AUTOSAR XML (schema 4-2-1)
standard types defined: boolean, uint16, uint32, uint8
package /VehicleProject
  system System
package /NM
  nm config NmConfig: can-nm-cluster-coupling=coupled-cluster=NIO_ES6_RF_CAN_SR_V3_0_CAN
    can nm cluster NIO_ES6_RF_CAN_SR_V3_0_CAN: communication-cluster=NIO_ES6_RF_CAN_SR_V3_0, nm-channel-id=0, nm-msg-cycle-time=0.64, nm-network-timeout=2, nm-repeat-message-time=3.2, nm-user-data-length=6, nm-wait-bus-sleep-time=2
      can nm node CGW: nm-if-ecu=CGW_CAN, nm-node-id=5, rx-nm-pdu=NM_WLC_oNIO_ES6_RF_CAN_SR_V3_0, tx-nm-pdu=NM_CGW_oNIO_ES6_RF_CAN_SR_V3_0, nm-msg-cycle-offset=0, nm-msg-reduced-time=0.32, nm-range-config={lower-can-id=1280, upper-can-id=1407}
      can nm node WLC: controller=CT_NIO_ES6_RF_CAN_SR_V3_0, nm-if-ecu=WLC_CAN, nm-node-id=56, rx-nm-pdu=NM_CGW_oNIO_ES6_RF_CAN_SR_V3_0, tx-nm-pdu=NM_WLC_oNIO_ES6_RF_CAN_SR_V3_0, nm-msg-cycle-offset=0, nm-msg-reduced-time=0.32, nm-range-config={lower-can-id=1280, upper-can-id=1407}
    nm-if-ecus:
      nm ecu CGW_CAN: nm-node-id-enabled=true, nm-user-data-enabled=true
      nm ecu WLC_CAN: ecu-instance=WLC, nm-node-id-enabled=true, nm-user-data-enabled=true
package /TP
  can tp config NIO_ES6_RF_CAN_SR_V3_0_CAN: communication-cluster=NIO_ES6_RF_CAN_SR_V3_0, can-tp-ecu{cycle-time-main-function=0.005, ecu-instance=WLC}
    can tp channel TPCH: channel-id=0, channel-mode=FULL-DUPLEX-MODE
    can-tp-connection addressing-format=STANDARD, can-tp-channel=TPCH, data-pdu=DIAG_REQ_AllECU_Tp_oNIO_ES6_RF_CAN_SR_V3_0, receiver=TN_WLC, ta-type=FUNCTIONAL, tp-sdu=DIAG_REQ_AllECU_oNIO_ES6_RF_CAN_SR_V3_0, transmitter=TN_CGW:
      ident DIAG_REQ_AllECU_oTN_CGW
    can-tp-connection addressing-format=STANDARD, can-tp-channel=TPCH, data-pdu=DIAG_REQ_WLC_Tp_oNIO_ES6_RF_CAN_SR_V3_0, flow-control-pdu=DIAG_RESP_WLC_Tp_oNIO_ES6_RF_CAN_SR_V3_0, receiver=TN_WLC, ta-type=PHYSICAL, tp-sdu=DIAG_REQ_WLC_oNIO_ES6_RF_CAN_SR_V3_0, transmitter=TN_CGW:
      ident DIAG_REQ_WLC_oTN_WLC
    can-tp-connection addressing-format=STANDARD, can-tp-channel=TPCH, data-pdu=DIAG_RESP_WLC_Tp_oNIO_ES6_RF_CAN_SR_V3_0, flow-control-pdu=DIAG_REQ_WLC_Tp_oNIO_ES6_RF_CAN_SR_V3_0, receiver=TN_CGW, ta-type=PHYSICAL, tp-sdu=DIAG_RESP_WLC_oNIO_ES6_RF_CAN_SR_V3_0, transmitter=TN_WLC:
      ident DIAG_RESP_WLC_oTN_WLC
    can tp node TN_CGW
    can tp node TN_WLC: connector=CN_NIO_ES6_RF_CAN_SR_V3_0
package /Cluster
  can cluster NIO_ES6_RF_CAN_SR_V3_0: baudrate=500000, protocol-name=CAN  # NIO_ES8_G_1_F_ES6_G1_2_RF_CAN_DraftRelease_V_B3_0_0_20181126
    can physical channel CHNL: comm-connectors=CN_NIO_ES6_RF_CAN_SR_V3_0
      frame BCU_04_oNIO_ES6_RF_CAN_SR_V3_0: id 0x5B, to WLC, frame-length=8, can-addressing-mode=STANDARD
        pdu BCU_04_oNIO_ES6_RF_CAN_SR_V3_0: length=8, minimum-delay=0, transmission-mode-false-timing=cyclic-timing={time-offset=0, time-period=0.02}, transmission-mode-true-timing=cyclic-timing={time-offset=0, time-period=0.02}, unused-bit-pattern=0
          signal VehSpd_oBCU_04_oNIO_ES6_RF_CAN_SR_V3_0: start 20, 13 bit, big-endian, init-value=0, base-type=uint16, compu {phys=raw*0.05625 for raw 0..6400; unit km/h}, unit=km/h, transfer-property=PENDING, to WLC(timeout 0.15 s)  # Vehicle speed. Invalid values 1901 - 1FFF
      frame CDC_IC_01_oNIO_ES6_RF_CAN_SR_V3_0: id 0x3AA, to WLC, frame-length=3, can-addressing-mode=STANDARD
        pdu CDC_IC_01_oNIO_ES6_RF_CAN_SR_V3_0: length=3, minimum-delay=0, transmission-mode-false-timing=cyclic-timing={time-offset=0, time-period=1}, transmission-mode-true-timing=cyclic-timing={time-offset=0, time-period=1}, unused-bit-pattern=0
          signal VehOdometer_oCDC_IC_01_oNIO_ES6_RF_CAN_SR_V3_0: start 7, 24 bit, big-endian, init-value=0, base-type=uint32, compu {identical}, range raw 0..16777214, unit=km, transfer-property=PENDING, to WLC(timeout 5 s)  # Vehicle odometer Invalid value FFFFFF
      frame CDC_WLC_oNIO_ES6_RF_CAN_SR_V3_0: id 0x2BA, to WLC, frame-length=1, can-addressing-mode=STANDARD
        pdu CDC_WLC_oNIO_ES6_RF_CAN_SR_V3_0: length=1, minimum-delay=0, transmission-mode-false-timing=cyclic-timing={time-offset=0, time-period=0.1}, transmission-mode-true-timing=cyclic-timing={time-offset=0, time-period=0.1}, unused-bit-pattern=0
          signal WLCChrgFctEnaReq_oCDC_WLC_oNIO_ES6_RF_CAN_SR_V3_0: start 1, 2 bit, big-endian, init-value=0, base-type=uint8, compu {0=Cx0_Disable_WLC_charging_function (Disable WLC charging function), 1=Cx1_Enable_WLC_charging_function (Enable WLC charging function), 2=Cx2_No_operation (No operation), 3=Cx3_Invalid}, transfer-property=PENDING, to WLC(timeout 0.5 s)  # Wireless charger (WLC) charging function enable/disable
      frame CDC_WLC_NFC_oNIO_ES6_RF_CAN_SR_V3_0: id 0x4AF, to WLC, frame-length=8, can-addressing-mode=STANDARD
        user defined pdu CDC_WLC_NFC_oNIO_ES6_RF_CAN_SR_V3_0: length=8
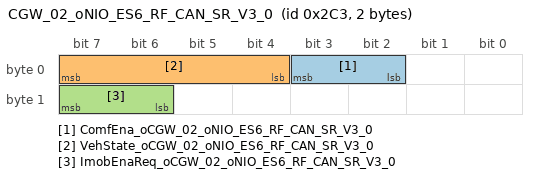
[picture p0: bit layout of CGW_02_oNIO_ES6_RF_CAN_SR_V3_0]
      frame CGW_02_oNIO_ES6_RF_CAN_SR_V3_0: id 0x2C3, to WLC, frame-length=2, can-addressing-mode=STANDARD
        pdu CGW_02_oNIO_ES6_RF_CAN_SR_V3_0: length=2, minimum-delay=0, transmission-mode-false-timing=cyclic-timing={time-offset=0, time-period=0.02}, transmission-mode-true-timing=cyclic-timing={time-offset=0, time-period=0.02}, unused-bit-pattern=0
          signal ComfEna_oCGW_02_oNIO_ES6_RF_CAN_SR_V3_0: start 3, 2 bit, big-endian, init-value=0, base-type=uint8, compu {0=Cx0_Comfort_not_enabled (Comfort not enabled), 1=Cx1_Comfort_enabled (Comfort enabled), 2=Cx2_Reserved, 3=Cx3_Invalid}, transfer-property=PENDING, to WLC(timeout 0.15 s)  # Comfort enable
          signal VehState_oCGW_02_oNIO_ES6_RF_CAN_SR_V3_0: start 7, 4 bit, big-endian, init-value=0, base-type=uint8, compu {0=Cx0_Parked_vehicle_Off_ (Parked vehicle(Off)), 1=Cx1_Driver_present_On_ (Driver present(On)), 2=Cx2_Driving, 3=Cx3_Software_update (Software update), 4=Cx4_Reserved, 5=Cx5_Reserved, 6=Cx6_Reserved, 7=Cx7_Reserved, 8=Cx8_Reserved, 9=Cx9_Reserved, 10=CxA_Reserved, 11=CxB_Reserved, 12=CxC_Reserved, 13=CxD_Reserved, 14=CxE_Reserved, 15=CxF_Invalid}, transfer-property=PENDING, to WLC(timeout 0.15 s)  # Vehicle state (Replaces vehicle power mode)
          signal ImobEnaReq_oCGW_02_oNIO_ES6_RF_CAN_SR_V3_0: start 15, 2 bit, big-endian, init-value=0, base-type=uint8, compu {0=Cx0_Disable, 1=Cx1_Enable_AID1 (Enable AID1), 2=Cx2_Enable_AID2 (Enable AID2), 3=Cx3_Invalid}, transfer-property=PENDING, to WLC(timeout 0.15 s)  # Immobilizer enable request to WLC
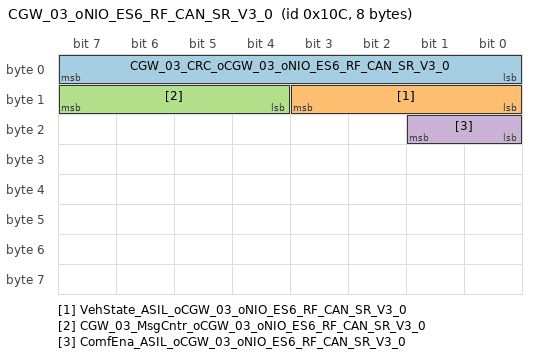
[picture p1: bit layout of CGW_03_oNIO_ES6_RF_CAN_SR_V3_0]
      frame CGW_03_oNIO_ES6_RF_CAN_SR_V3_0: id 0x10C, to WLC, frame-length=8, can-addressing-mode=STANDARD
        pdu CGW_03_oNIO_ES6_RF_CAN_SR_V3_0: length=8, minimum-delay=0, transmission-mode-false-timing=cyclic-timing={time-offset=0, time-period=0.02}, transmission-mode-true-timing=cyclic-timing={time-offset=0, time-period=0.02}, unused-bit-pattern=0
          signal CGW_03_CRC_oCGW_03_oNIO_ES6_RF_CAN_SR_V3_0: start 7, 8 bit, big-endian, init-value=0, base-type=uint8, compu {identical}, range raw 0..255, transfer-property=PENDING, to WLC(timeout 0.15 s)  # CGW_03 CRC
          signal VehState_ASIL_oCGW_03_oNIO_ES6_RF_CAN_SR_V3_0: start 11, 4 bit, big-endian, init-value=0, base-type=uint8, compu {0=Cx0_Parked_vehicle_Off_ (Parked vehicle(Off)), 1=Cx1_Driver_present_On_ (Driver present(On)), 2=Cx2_Driving, 3=Cx3_Software_update (Software update), 4=Cx4_Reserved, 5=Cx5_Reserved, 6=Cx6_Reserved, 7=Cx7_Reserved, 8=Cx8_Reserved, 9=Cx9_Reserved, 10=CxA_Reserved, 11=CxB_Reserved, 12=CxC_Reserved, 13=CxD_Reserved, 14=CxE_Reserved, 15=CxF_Invalid}, transfer-property=PENDING, to WLC(timeout 0.15 s)  # Vehicle state ASIL requirement(Replaces vehicle power mode)
          signal CGW_03_MsgCntr_oCGW_03_oNIO_ES6_RF_CAN_SR_V3_0: start 15, 4 bit, big-endian, init-value=0, base-type=uint8, compu {identical}, range raw 0..15, transfer-property=PENDING, to WLC(timeout 0.15 s)  # CGW_03 message counter
          signal ComfEna_ASIL_oCGW_03_oNIO_ES6_RF_CAN_SR_V3_0: start 17, 2 bit, big-endian, init-value=0, base-type=uint8, compu {0=Cx0_Comfort_not_enabled (Comfort not enabled), 1=Cx1_Comfort_enabled (Comfort enabled), 2=Cx2_Reserved, 3=Cx3_Invalid}, transfer-property=PENDING, to WLC(timeout 0.15 s)  # Comfort enable ASIL requirement
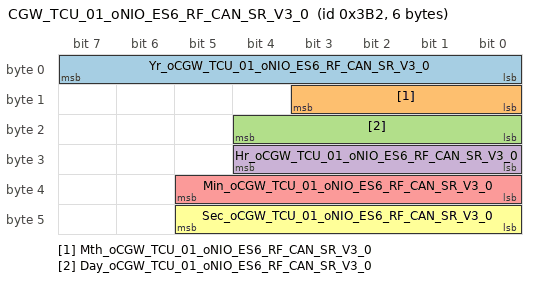
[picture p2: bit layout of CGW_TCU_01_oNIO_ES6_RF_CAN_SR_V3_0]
      frame CGW_TCU_01_oNIO_ES6_RF_CAN_SR_V3_0: id 0x3B2, to WLC, frame-length=6, can-addressing-mode=STANDARD
        pdu CGW_TCU_01_oNIO_ES6_RF_CAN_SR_V3_0: length=6, minimum-delay=0, transmission-mode-false-timing=cyclic-timing={time-offset=0, time-period=1}, transmission-mode-true-timing=cyclic-timing={time-offset=0, time-period=1}, unused-bit-pattern=0
          signal Yr_oCGW_TCU_01_oNIO_ES6_RF_CAN_SR_V3_0: start 7, 8 bit, big-endian, init-value=0, base-type=uint8, compu {phys=raw+2000 for raw 0..254; unit Year}, unit=Year, transfer-property=PENDING, to WLC(timeout 5 s)  # Year Invalid values FF
          signal Mth_oCGW_TCU_01_oNIO_ES6_RF_CAN_SR_V3_0: start 11, 4 bit, big-endian, init-value=0, base-type=uint8, compu {0=Cx0_Unknown, 1=Cx1_January, 2=Cx2_February, 3=Cx3_March, 4=Cx4_April, 5=Cx5_May, 6=Cx6_June, 7=Cx7_July, 8=Cx8_August, 9=Cx9_September, 10=CxA_October, 11=CxB_November, 12=CxC_December, 13=CxD_Reserved, 14=CxE_Reserved, 15=CxF_Invalid}, transfer-property=PENDING, to WLC(timeout 5 s)  # Month Invalid value F
          signal Day_oCGW_TCU_01_oNIO_ES6_RF_CAN_SR_V3_0: start 20, 5 bit, big-endian, init-value=0, base-type=uint8, compu {identical}, range raw 0..31, unit=Day, transfer-property=PENDING, to WLC(timeout 5 s)
          signal Hr_oCGW_TCU_01_oNIO_ES6_RF_CAN_SR_V3_0: start 28, 5 bit, big-endian, init-value=0, base-type=uint8, compu {identical}, range raw 0..23, unit=Hour, transfer-property=PENDING, to WLC(timeout 5 s)  # Hour Reserved 18 - 1E Invalid values 1F
          signal Min_oCGW_TCU_01_oNIO_ES6_RF_CAN_SR_V3_0: start 37, 6 bit, big-endian, init-value=0, base-type=uint8, compu {identical}, range raw 0..59, unit=min, transfer-property=PENDING, to WLC(timeout 5 s)  # Minute Reserved 3C - 3E Invalid values 3F
          signal Sec_oCGW_TCU_01_oNIO_ES6_RF_CAN_SR_V3_0: start 45, 6 bit, big-endian, init-value=0, base-type=uint8, compu {identical}, range raw 0..59, unit=Sec, transfer-property=PENDING, to WLC(timeout 5 s)  # Second Reserved 3C - 3E Invalid values 3F
      frame CGW_WLC_oNIO_ES6_RF_CAN_SR_V3_0: id 0x3BE, to WLC, frame-length=8, can-addressing-mode=STANDARD
        pdu CGW_WLC_oNIO_ES6_RF_CAN_SR_V3_0: length=8, minimum-delay=0, transmission-mode-false-timing=cyclic-timing={time-offset=0, time-period=1}, transmission-mode-true-timing=cyclic-timing={time-offset=0, time-period=1}, unused-bit-pattern=0
          signal CGW_WLC_CRC_oCGW_WLC_oNIO_ES6_RF_CAN_SR_V3_0: start 7, 8 bit, big-endian, init-value=0, base-type=uint8, compu {identical}, range raw 0..255, transfer-property=PENDING, to WLC(timeout 5 s)  # CGW_WLC CRC
          signal CGW_WLC_MsgCntr_oCGW_WLC_oNIO_ES6_RF_CAN_SR_V3_0: start 15, 4 bit, big-endian, init-value=0, base-type=uint8, compu {identical}, range raw 0..15, transfer-property=PENDING, to WLC(timeout 5 s)  # CGW_WLC message counter
      frame DIAG_REQ_AllECU_oNIO_ES6_RF_CAN_SR_V3_0: id 0x601, to WLC, frame-length=8, can-addressing-mode=STANDARD
        n pdu DIAG_REQ_AllECU_Tp_oNIO_ES6_RF_CAN_SR_V3_0: length=8
      frame DIAG_REQ_WLC_oNIO_ES6_RF_CAN_SR_V3_0: id 0x638, to WLC, frame-length=8, can-addressing-mode=STANDARD
        n pdu DIAG_REQ_WLC_Tp_oNIO_ES6_RF_CAN_SR_V3_0: length=8
      frame DIAG_RESP_WLC_oNIO_ES6_RF_CAN_SR_V3_0: id 0x6B8, from WLC, frame-length=8, can-addressing-mode=STANDARD
        n pdu DIAG_RESP_WLC_Tp_oNIO_ES6_RF_CAN_SR_V3_0: length=8
      frame IMOB_CGW_WLC_oNIO_ES6_RF_CAN_SR_V3_0: id 0x27, to WLC, frame-length=8, can-addressing-mode=STANDARD
        user defined pdu IMOB_CGW_WLC_oNIO_ES6_RF_CAN_SR_V3_0: length=8
      frame IMOB_WLC_CGW_oNIO_ES6_RF_CAN_SR_V3_0: id 0x28, from WLC, frame-length=8, can-addressing-mode=STANDARD
        user defined pdu IMOB_WLC_CGW_oNIO_ES6_RF_CAN_SR_V3_0: length=8
      frame NM_CGW_oNIO_ES6_RF_CAN_SR_V3_0: id 0x505, to WLC, frame-length=8, can-addressing-mode=STANDARD
        nm pdu NM_CGW_oNIO_ES6_RF_CAN_SR_V3_0: length=8, unused-bit-pattern=0
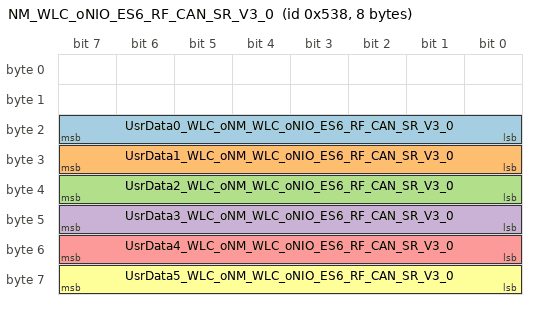
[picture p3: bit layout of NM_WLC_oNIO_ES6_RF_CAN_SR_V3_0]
      frame NM_WLC_oNIO_ES6_RF_CAN_SR_V3_0: id 0x538, from WLC, frame-length=8, can-addressing-mode=STANDARD
        nm pdu NM_WLC_oNIO_ES6_RF_CAN_SR_V3_0: length=8, unused-bit-pattern=0
          signal UsrData0_WLC_oNM_WLC_oNIO_ES6_RF_CAN_SR_V3_0: start 23, 8 bit, big-endian, init-value=0, base-type=uint8, compu {identical}, range raw 0..255, transfer-property=PENDING  # User data 0 WLC
          signal UsrData1_WLC_oNM_WLC_oNIO_ES6_RF_CAN_SR_V3_0: start 31, 8 bit, big-endian, init-value=0, base-type=uint8, compu {identical}, range raw 0..255, transfer-property=PENDING  # User data 1 WLC
          signal UsrData2_WLC_oNM_WLC_oNIO_ES6_RF_CAN_SR_V3_0: start 39, 8 bit, big-endian, init-value=0, base-type=uint8, compu {identical}, range raw 0..255, transfer-property=PENDING  # User data 2 WLC
          signal UsrData3_WLC_oNM_WLC_oNIO_ES6_RF_CAN_SR_V3_0: start 47, 8 bit, big-endian, init-value=0, base-type=uint8, compu {identical}, range raw 0..255, transfer-property=PENDING  # User data 3 WLC
          signal UsrData4_WLC_oNM_WLC_oNIO_ES6_RF_CAN_SR_V3_0: start 55, 8 bit, big-endian, init-value=0, base-type=uint8, compu {identical}, range raw 0..255, transfer-property=PENDING  # User data 4 WLC
          signal UsrData5_WLC_oNM_WLC_oNIO_ES6_RF_CAN_SR_V3_0: start 63, 8 bit, big-endian, init-value=0, base-type=uint8, compu {identical}, range raw 0..255, transfer-property=PENDING  # User data 5 WLC
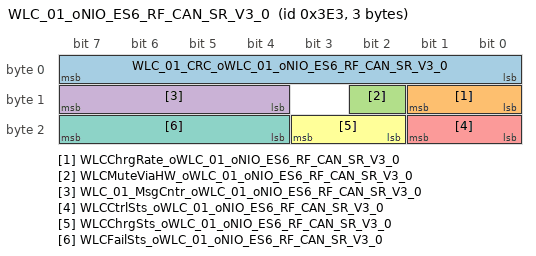
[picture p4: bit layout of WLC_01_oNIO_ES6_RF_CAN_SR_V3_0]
      frame WLC_01_oNIO_ES6_RF_CAN_SR_V3_0: id 0x3E3, from WLC, frame-length=3, can-addressing-mode=STANDARD
        pdu WLC_01_oNIO_ES6_RF_CAN_SR_V3_0: length=3, minimum-delay=0, transmission-mode-false-timing=cyclic-timing={time-offset=0, time-period=1}, transmission-mode-true-timing=cyclic-timing={time-offset=0, time-period=1}, unused-bit-pattern=0
          signal WLC_01_CRC_oWLC_01_oNIO_ES6_RF_CAN_SR_V3_0: start 7, 8 bit, big-endian, init-value=0, base-type=uint8, compu {identical}, range raw 0..255, transfer-property=PENDING  # WLC_01 CRC
          signal WLCChrgRate_oWLC_01_oNIO_ES6_RF_CAN_SR_V3_0: start 9, 2 bit, big-endian, init-value=0, base-type=uint8, compu {0=Cx0_Not_started_ (Not started), 1=Cx1_Power_Requested_ (Power Requested), 2=Cx2_Power_Reduced_ (Power Reduced), 3=Cx3_Reserved}, transfer-property=PENDING  # Wireless charger (WLC) charge rate
          signal WLCMuteViaHW_oWLC_01_oNIO_ES6_RF_CAN_SR_V3_0: start 10, 1 bit, big-endian, init-value=0, base-type=boolean, compu {0=Cx0_Active_Muted_ (Active (Muted)), 1=Cx1_Inactive_Not_muted_ (Inactive (Not muted))}, transfer-property=PENDING  # Mute line status
          signal WLC_01_MsgCntr_oWLC_01_oNIO_ES6_RF_CAN_SR_V3_0: start 15, 4 bit, big-endian, init-value=0, base-type=uint8, compu {identical}, range raw 0..15, transfer-property=PENDING  # WLC_01 Message counter
          signal WLCCtrlSts_oWLC_01_oNIO_ES6_RF_CAN_SR_V3_0: start 17, 2 bit, big-endian, init-value=0, base-type=uint8, compu {0=Cx0_WLC_enabled (WLC enabled), 1=Cx1_WLC_disabled (WLC disabled), 2=Cx2_Reserved, 3=Cx3_Invalid}, transfer-property=PENDING  # Wireless charger (WLC) control status
          signal WLCChrgSts_oWLC_01_oNIO_ES6_RF_CAN_SR_V3_0: start 19, 2 bit, big-endian, init-value=0, base-type=uint8, compu {0=Cx0_WLC_stopped (WLC stopped), 1=Cx1_WLC_on_going (WLC on going), 2=Cx2_Charge_complete (Charge complete), 3=Cx3_Invalid}, transfer-property=PENDING  # Wireless charger (WLC) charging status
          signal WLCFailSts_oWLC_01_oNIO_ES6_RF_CAN_SR_V3_0: start 23, 4 bit, big-endian, init-value=0, base-type=uint8, compu {0=Cx0_No_failure (No failure), 1=Cx1_Over_temperature (Over temperature), 2=Cx2_Under_voltage (Under voltage), 3=Cx3_Over_voltage (Over voltage), 4=Cx4_Internal_error (Internal error), 5=Cx5_Foreign_object_existing (Foreign object existing), 6=Cx6_Unknown_error (Unknown error), 7=Cx7_Smartphone_no_response_or_error (Smartphone no response or error), 8=Cx8_Conductive_Device_Detected (Conductive Device Detected), 9=Cx9_Reserved, 10=CxA_Reserved, 11=CxB_Reserved, 12=CxC_Reserved, 13=CxD_Reserved, 14=CxE_Reserved, 15=CxF_Invalid}, transfer-property=PENDING  # Wireless charger (WLC) fail status
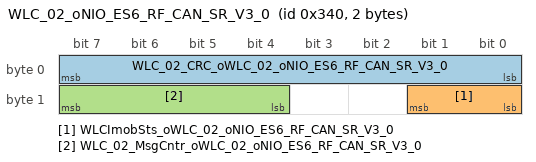
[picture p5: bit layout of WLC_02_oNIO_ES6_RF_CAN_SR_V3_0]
      frame WLC_02_oNIO_ES6_RF_CAN_SR_V3_0: id 0x340, from WLC, frame-length=2, can-addressing-mode=STANDARD
        pdu WLC_02_oNIO_ES6_RF_CAN_SR_V3_0: length=2, minimum-delay=0, transmission-mode-false-timing=cyclic-timing={time-offset=0, time-period=0.1}, transmission-mode-true-timing=cyclic-timing={time-offset=0, time-period=0.1}, unused-bit-pattern=0
          signal WLC_02_CRC_oWLC_02_oNIO_ES6_RF_CAN_SR_V3_0: start 7, 8 bit, big-endian, init-value=0, base-type=uint8, compu {identical}, range raw 0..255, transfer-property=PENDING  # WLC_02 CRC
          signal WLCImobSts_oWLC_02_oNIO_ES6_RF_CAN_SR_V3_0: start 9, 2 bit, big-endian, init-value=0, base-type=uint8, compu {0=Cx0_Disable, 1=Cx1_Enable, 2=Cx2_Reserved, 3=Cx3_Invalid}, transfer-property=PENDING  # WLC Immo Status
          signal WLC_02_MsgCntr_oWLC_02_oNIO_ES6_RF_CAN_SR_V3_0: start 15, 4 bit, big-endian, init-value=0, base-type=uint8, compu {identical}, range raw 0..15, transfer-property=PENDING  # WLC_02 Message counter
      frame WLC_CDC_NFC_oNIO_ES6_RF_CAN_SR_V3_0: id 0x4AE, from WLC, frame-length=8, can-addressing-mode=STANDARD
        user defined pdu WLC_CDC_NFC_oNIO_ES6_RF_CAN_SR_V3_0: length=8
      frame WLC_DEVLP_01_oNIO_ES6_RF_CAN_SR_V3_0: id 0x4BB, from WLC, frame-length=8, can-addressing-mode=STANDARD
        user defined pdu WLC_DEVLP_01_oNIO_ES6_RF_CAN_SR_V3_0: length=8
      frame WLC_DEVLP_02_oNIO_ES6_RF_CAN_SR_V3_0: id 0x4BC, to WLC, frame-length=8, can-addressing-mode=STANDARD
        user defined pdu WLC_DEVLP_02_oNIO_ES6_RF_CAN_SR_V3_0: length=8
      pdu triggering PT_DIAG_REQ_AllECU: pdu=DIAG_REQ_AllECU_oNIO_ES6_RF_CAN_SR_V3_0, to WLC
      pdu triggering PT_DIAG_REQ_WLC: pdu=DIAG_REQ_WLC_oNIO_ES6_RF_CAN_SR_V3_0, to WLC
      pdu triggering PT_DIAG_RESP_WLC: pdu=DIAG_RESP_WLC_oNIO_ES6_RF_CAN_SR_V3_0, from WLC
package /ECU
  ecu instance WLC: associated-com-i-pdu-group=[WLC_oNIO_ES6_RF_CAN_SR_V3_0_Rx, WLC_oNIO_ES6_RF_CAN_SR_V3_0_Tx]
    can communication controller CT_NIO_ES6_RF_CAN_SR_V3_0
    can communication connector CN_NIO_ES6_RF_CAN_SR_V3_0: comm-controller=CT_NIO_ES6_RF_CAN_SR_V3_0
package /IPDUGroup
  i signal i pdu group WLC_oNIO_ES6_RF_CAN_SR_V3_0_Rx: communication-direction=IN
    i-signal-i-pdus:
      BCU_04_oNIO_ES6_RF_CAN_SR_V3_0
      CDC_IC_01_oNIO_ES6_RF_CAN_SR_V3_0
      CDC_WLC_oNIO_ES6_RF_CAN_SR_V3_0
      CGW_02_oNIO_ES6_RF_CAN_SR_V3_0
      CGW_03_oNIO_ES6_RF_CAN_SR_V3_0
      CGW_TCU_01_oNIO_ES6_RF_CAN_SR_V3_0
      CGW_WLC_oNIO_ES6_RF_CAN_SR_V3_0
  i signal i pdu group WLC_oNIO_ES6_RF_CAN_SR_V3_0_Tx: communication-direction=OUT, i-signal-i-pdus=[WLC_01_oNIO_ES6_RF_CAN_SR_V3_0, WLC_02_oNIO_ES6_RF_CAN_SR_V3_0]
package /PDU
  dcm i pdu DIAG_REQ_AllECU_oNIO_ES6_RF_CAN_SR_V3_0: length=7, diag-pdu-type=DIAG-REQUEST
  dcm i pdu DIAG_REQ_WLC_oNIO_ES6_RF_CAN_SR_V3_0: length=8, diag-pdu-type=DIAG-REQUEST
  dcm i pdu DIAG_RESP_WLC_oNIO_ES6_RF_CAN_SR_V3_0: length=8, diag-pdu-type=DIAG-RESPONSE
package /DataType/Unit
  7 x unit:
    U_Day: display-name=Day
    U_Hour: display-name=Hour
    U_km: display-name=km
    U_kmYh: display-name=km/h
    U_min: display-name=min
    U_Sec: display-name=Sec
    U_Year: display-name=Year
